VERSION "Volvo_J1939_Proprietary_v1.0"

NS_ :

BS_:

BU_: EMS_Volvo ACM_Volvo

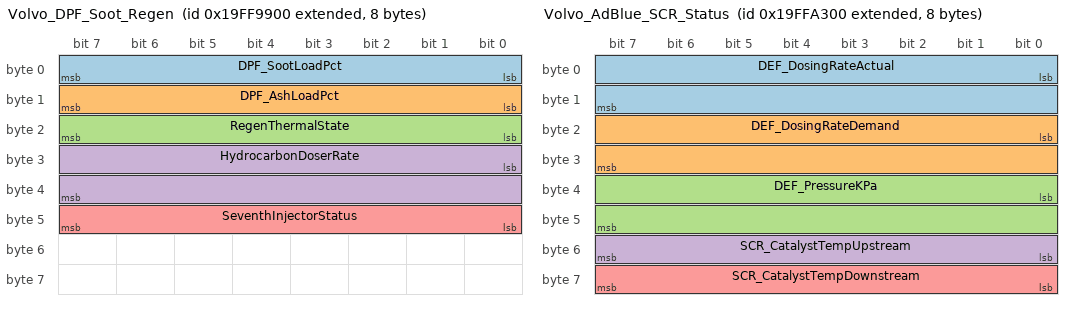
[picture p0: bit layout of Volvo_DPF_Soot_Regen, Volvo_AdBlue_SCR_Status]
BO_ 2583664896 Volvo_DPF_Soot_Regen: 8 EMS_Volvo
 SG_ DPF_SootLoadPct : 0|8@1+ (0.5,0) [0|100] "%" Vector__XXX
 SG_ DPF_AshLoadPct : 8|8@1+ (0.5,0) [0|100] "%" Vector__XXX
 SG_ RegenThermalState : 16|8@1+ (1,0) [0|255] "" Vector__XXX
 SG_ HydrocarbonDoserRate : 24|16@1+ (0.01,0) [0|655.35] "g/h" Vector__XXX
 SG_ SeventhInjectorStatus : 40|8@1+ (1,0) [0|255] "" Vector__XXX

BO_ 2583667456 Volvo_AdBlue_SCR_Status: 8 ACM_Volvo
 SG_ DEF_DosingRateActual : 0|16@1+ (0.1,0) [0|6553.5] "g/h" Vector__XXX
 SG_ DEF_DosingRateDemand : 16|16@1+ (0.1,0) [0|6553.5] "g/h" Vector__XXX
 SG_ DEF_PressureKPa : 32|16@1+ (1,0) [0|65535] "kPa" Vector__XXX
 SG_ SCR_CatalystTempUpstream : 48|8@1+ (5,-40) [-40|1235] "degC" Vector__XXX
 SG_ SCR_CatalystTempDownstream : 56|8@1+ (5,-40) [-40|1235] "degC" Vector__XXX

CM_ "Volvo Truck & Construction Equipment (D11/D13/D16, V-MAC, ACM, Tea2+) Proprietary J1939 DBC";
CM_ BO_ 2583664896 "PGN 65401 (0xFF79): Volvo DPF Soot/Ash Load and 7th Hydrocarbon Injector Telemetry";
CM_ BO_ 2583667456 "PGN 65411 (0xFF83): Volvo Aftertreatment ACM AdBlue/DEF Dosing and SCR Temperatures";

VAL_ 2583664896 RegenThermalState 0 "Cold" 1 "Warming Up" 2 "Active Bed Temp" 3 "High Exotherm" 4 "Cooling Down" ;
VAL_ 2583664896 SeventhInjectorStatus 0 "Inactive" 1 "Priming" 2 "Dosing Active" 3 "Purging" 4 "Fault" ;
